# MDR32F02 register map
File version: 1.5.0
CPU: BM-310S, little endian
Registers are 32-bit, read-write, no defined reset value unless marked. A register's access mark holds for its fields unless they carry their own. Offsets are from the block's base; [hi:lo] are bit positions; {n}, {i} and the like mark numbered series.

## I2C — I2C description
Base 0x40030000
0x00 PRL — PRL description
  [7:0] PR — PR description
0x04 PRH — PRH description
  [7:0] PR — PR description
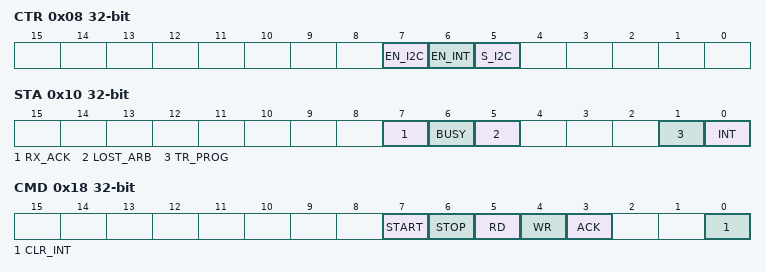
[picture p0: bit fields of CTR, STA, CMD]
0x08 CTR — CTR description
  [7] EN_I2C — EN_I2C description
  [6] EN_INT — EN_INT description
  [5] S_I2C — S_I2C description
0x0C RXD — RXD description
  [7:0] RXD
0x10 STA — STA description
  [7] RX_ACK — RX_ACK description
  [6] BUSY — BUSY description
  [5] LOST_ARB — LOST_ARB description
  [1] TR_PROG — TR_PROG description
  [0] INT — INT description
0x14 TXD — TXD description
  [7:0] TXD
0x18 CMD — CMD description
  [7] START — START description
  [6] STOP — STOP description
  [5] RD — RD description
  [4] WR — WR description
  [3] ACK — ACK description
  [0] CLR_INT — CLR_INT description

## ADC — ADC description
Base 0x40040000
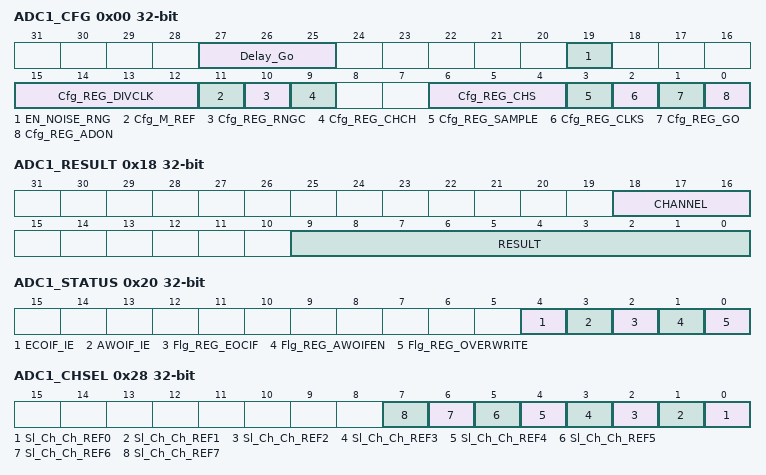
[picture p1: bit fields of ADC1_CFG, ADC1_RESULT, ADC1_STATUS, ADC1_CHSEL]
0x00 ADC1_CFG — ADC1_CFG description
  [27:25] Delay_Go — Delay_Go description
  [19] EN_NOISE_RNG — EN_NOISE_RNG description
  [15:12] Cfg_REG_DIVCLK — Cfg_REG_DIVCLK description
  [11] Cfg_M_REF — Cfg_M_REF description
  [10] Cfg_REG_RNGC — Cfg_REG_RNGC description
  [9] Cfg_REG_CHCH — Cfg_REG_CHCH description
  [6:4] Cfg_REG_CHS — Cfg_REG_CHS description
  [3] Cfg_REG_SAMPLE — Cfg_REG_SAMPLE description
  [2] Cfg_REG_CLKS — Cfg_REG_CLKS description
  [1] Cfg_REG_GO — Cfg_REG_GO description
  [0] Cfg_REG_ADON — Cfg_REG_ADON description
0x08 ADC1_H_LEVEL — ADC1_H_LEVEL description
  [9:0] REG_H_LEVEL — REG_H_LEVEL description
0x10 ADC1_L_LEVEL — ADC1_L_LEVEL description
  [9:0] REG_L_LEVEL — REG_L_LEVEL description
0x18 ADC1_RESULT — ADC1_RESULT description
  [18:16] CHANNEL — CHANNEL description
  [9:0] RESULT — RESULT description
0x20 ADC1_STATUS — ADC1_STATUS description
  [4] ECOIF_IE — ECOIF_IE description
  [3] AWOIF_IE — AWOIF_IE description
  [2] Flg_REG_EOCIF — Flg_REG_EOCIF description
  [1] Flg_REG_AWOIFEN — Flg_REG_AWOIFEN description
  [0] Flg_REG_OVERWRITE — Flg_REG_OVERWRITE description
0x28 ADC1_CHSEL — ADC1_CHSEL description
  [n] Sl_Ch_Ch_REF{n} (n=0..7) — Sl_Ch_Ch_REF{n} description
0x30 ADC_TRIM — ADC_TRIM description
  [5:1] BG_TRIM — BG_TRIM description

## WWDG — WWDG description
Base 0x40048000
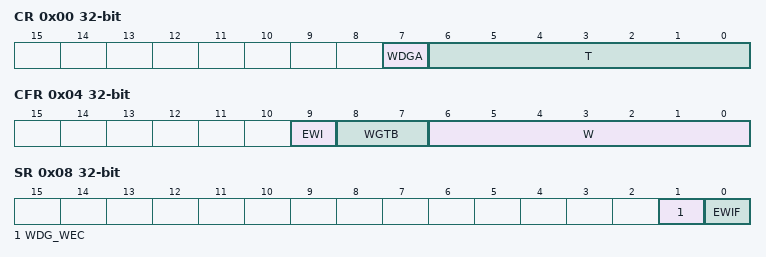
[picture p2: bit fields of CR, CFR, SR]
0x00 CR — CR description
  [7] WDGA — WDGA description
  [6:0] T — T description
0x04 CFR — CFR description
  [9] EWI — EWI description
  [8:7] WGTB — WGTB description
  [6:0] W — W description
0x08 SR — SR description
  [1] WDG_WEC — WDG_WEC description
  [0] EWIF — EWIF description

## IWDG — IWDG description
Base 0x40050000
0x00 KR — KR description
  [15:0] KEY — KEY description
0x04 PR — PR description
  [2:0] PR
0x08 RLR — RLR description
  [11:0] RLR
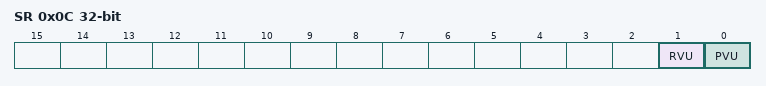
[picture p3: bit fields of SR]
0x0C SR — SR description
  [1] RVU — RVU description
  [0] PVU — PVU description

## POWER — POWER description
Base 0x40058000
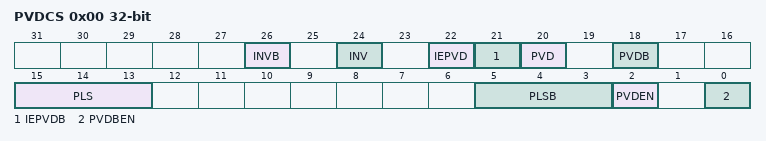
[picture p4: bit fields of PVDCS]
0x00 PVDCS — PVDCS description
  [26] INVB — INVB description
  [24] INV — INV description
  [22] IEPVD — IEPVD description
  [21] IEPVDB — IEPVDB description
  [20] PVD — PVD description
  [18] PVDB — PVDB description
  [15:13] PLS — PLS description
  [5:3] PLSB — PLSB description
  [2] PVDEN — PVDEN description
  [0] PVDBEN — PVDBEN description

## TIMER1 — TIMER1 description
Base 0x40070000
Same registers: TIMER2 0x40078000, TIMER3 0x400D8000, TIMER4 0x400E0000
0x00 CNT — CNT description
0x04 PSG — PSG description
0x08 ARR — ARR description
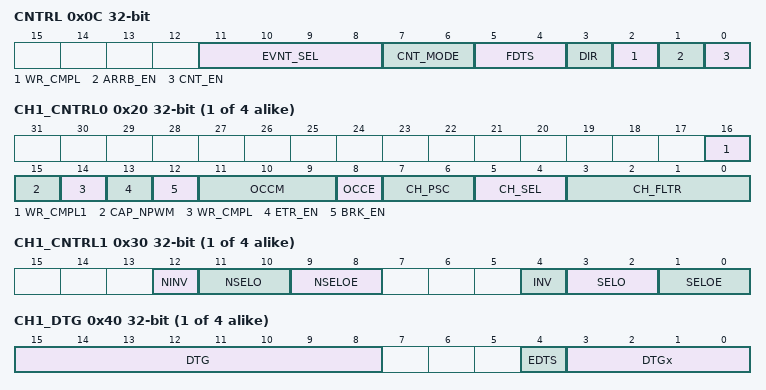
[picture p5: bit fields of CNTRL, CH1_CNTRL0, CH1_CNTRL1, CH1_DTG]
0x0C CNTRL — CNTRL description
  [11:8] EVNT_SEL — EVNT_SEL description
  [7:6] CNT_MODE — CNT_MODE description
  [5:4] FDTS — FDTS description
  [3] DIR — DIR description
  [2] WR_CMPL ro — WR_CMPL description
  [1] ARRB_EN — ARRB_EN description
  [0] CNT_EN — CNT_EN description
{0xC+4i} CH{i}_CCR (i=1..4) — CH{i}_CCR description
{0x1C+4i} CH{i}_CNTRL0 (i=1..4) — CH{i}_CNTRL0 description
  [16] WR_CMPL1 ro — WR_CMPL1 description
  [15] CAP_NPWM — CAP_NPWM description
  [14] WR_CMPL ro — WR_CMPL description
  [13] ETR_EN — ETR_EN description
  [12] BRK_EN — BRK_EN description
  [11:9] OCCM — OCCM description
  [8] OCCE — OCCE description
  [7:6] CH_PSC — CH_PSC description
  [5:4] CH_SEL — CH_SEL description
  [3:0] CH_FLTR — CH_FLTR description
{0x2C+4i} CH{i}_CNTRL1 (i=1..4) — CH{i}_CNTRL1 description
  [12] NINV — NINV description
  [11:10] NSELO — NSELO description
  [9:8] NSELOE — NSELOE description
  [4] INV — INV description
  [3:2] SELO — SELO description
  [1:0] SELOE — SELOE description
{0x3C+4i} CH{i}_DTG (i=1..4) — CH{i}_DTG description
  [15:8] DTG — DTG description
  [4] EDTS — EDTS description
  [3:0] DTGx — DTGx description
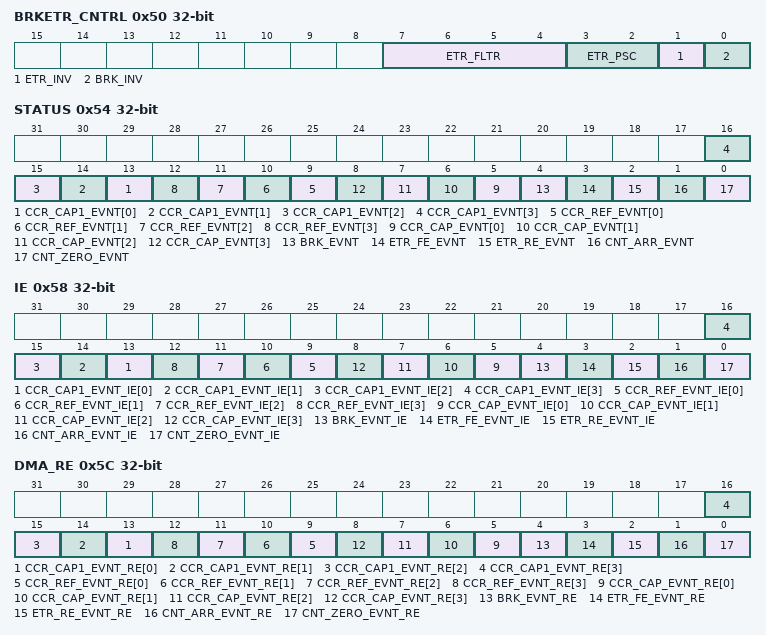
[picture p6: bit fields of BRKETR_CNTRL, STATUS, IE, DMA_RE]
0x50 BRKETR_CNTRL — BRKETR_CNTRL description
  [7:4] ETR_FLTR — ETR_FLTR description
  [3:2] ETR_PSC — ETR_PSC description
  [1] ETR_INV — ETR_INV description
  [0] BRK_INV — BRK_INV description
0x54 STATUS — STATUS description
  [n+13] CCR_CAP1_EVNT[{n}] (n=0..3) — CCR_CAP1_EVNT[{n}] description
  [n+9] CCR_REF_EVNT[{n}] (n=0..3) — CCR_REF_EVNT[{n}] description
  [n+5] CCR_CAP_EVNT[{n}] (n=0..3) — CCR_CAP_EVNT[{n}] description
  [4] BRK_EVNT — BRK_EVNT description
  [3] ETR_FE_EVNT — ETR_FE_EVNT description
  [2] ETR_RE_EVNT — ETR_RE_EVNT description
  [1] CNT_ARR_EVNT — CNT_ARR_EVNT description
  [0] CNT_ZERO_EVNT — CNT_ZERO_EVNT description
0x58 IE — IE description
  [n+13] CCR_CAP1_EVNT_IE[{n}] (n=0..3) — CCR_CAP1_EVNT_IE[{n}] description
  [n+9] CCR_REF_EVNT_IE[{n}] (n=0..3) — CCR_REF_EVNT_IE[{n}] description
  [n+5] CCR_CAP_EVNT_IE[{n}] (n=0..3) — CCR_CAP_EVNT_IE[{n}] description
  [4] BRK_EVNT_IE — BRK_EVNT_IE description
  [3] ETR_FE_EVNT_IE — ETR_FE_EVNT_IE description
  [2] ETR_RE_EVNT_IE — ETR_RE_EVNT_IE description
  [1] CNT_ARR_EVNT_IE — CNT_ARR_EVNT_IE description
  [0] CNT_ZERO_EVNT_IE — CNT_ZERO_EVNT_IE description
0x5C DMA_RE — DMA_RE description
  [n+13] CCR_CAP1_EVNT_RE[{n}] (n=0..3) — CCR_CAP1_EVNT_RE[{n}] description
  [n+9] CCR_REF_EVNT_RE[{n}] (n=0..3) — CCR_REF_EVNT_RE[{n}] description
  [n+5] CCR_CAP_EVNT_RE[{n}] (n=0..3) — CCR_CAP_EVNT_RE[{n}] description
  [4] BRK_EVNT_RE — BRK_EVNT_RE description
  [3] ETR_FE_EVNT_RE — ETR_FE_EVNT_RE description
  [2] ETR_RE_EVNT_RE — ETR_RE_EVNT_RE description
  [1] CNT_ARR_EVNT_RE — CNT_ARR_EVNT_RE description
  [0] CNT_ZERO_EVNT_RE — CNT_ZERO_EVNT_RE description
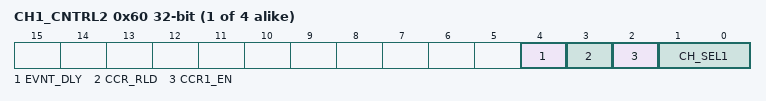
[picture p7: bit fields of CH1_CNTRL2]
{0x5C+4i} CH{i}_CNTRL2 (i=1..4) — CH{i}_CNTRL2 description
  [4] EVNT_DLY — EVNT_DLY description
  [3] CCR_RLD — CCR_RLD description
  [2] CCR1_EN — CCR1_EN description
  [1:0] CH_SEL1 — CH_SEL1 description
{0x6C+4i} CH{i}_CCR1 (i=1..4) — CH{i}_CCR1 description
